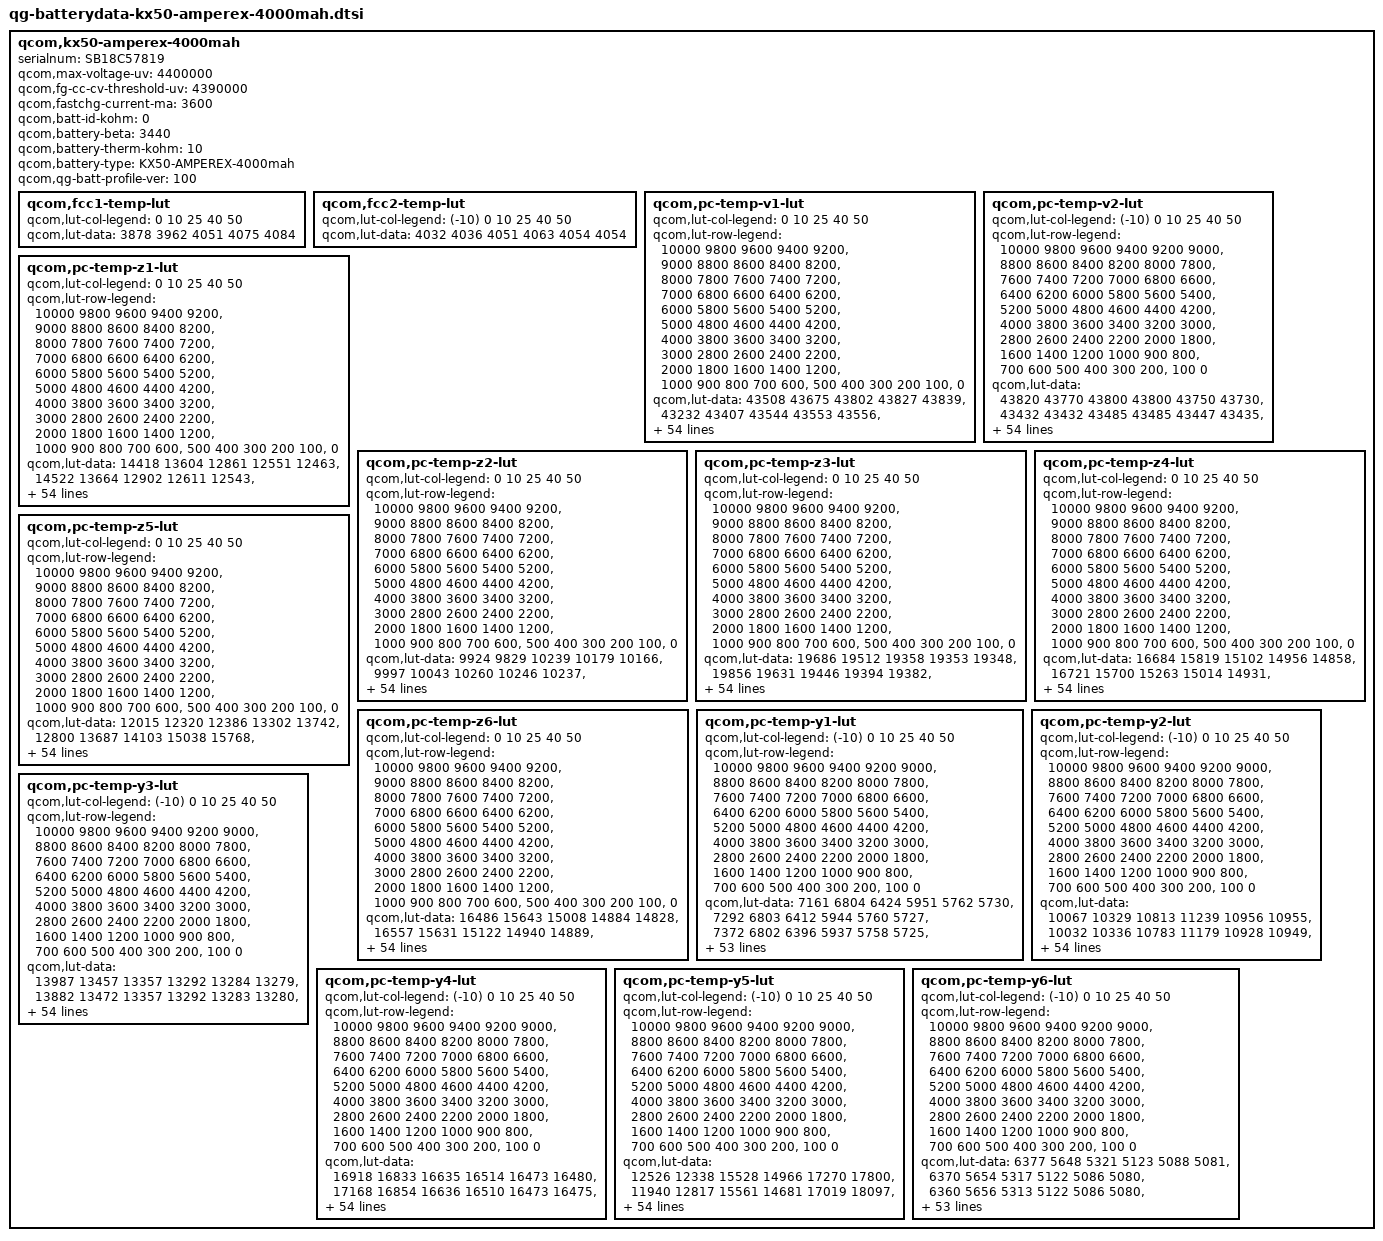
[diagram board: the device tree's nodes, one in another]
qcom,kx50-amperex-4000mah {
    /* 4151556_Lenovo_Sofia_ATL_4000mAH_PMI632_averaged_MasterSlave_Aug13th2019 */
    serialnum = "SB18C57819";
    qcom,max-voltage-uv = <4400000>;
    qcom,fg-cc-cv-threshold-uv = <4390000>;
    qcom,fastchg-current-ma = <3600>;
    qcom,batt-id-kohm = <0>;
    qcom,battery-beta = <3440>;
    qcom,battery-therm-kohm = <10>;
    qcom,battery-type = "KX50-AMPEREX-4000mah";
    qcom,qg-batt-profile-ver = <100>;

	qcom,fcc1-temp-lut {
		qcom,lut-col-legend = <0 10 25 40 50>;
		qcom,lut-data = <3878 3962 4051 4075 4084>;
	};

	qcom,fcc2-temp-lut {
		qcom,lut-col-legend = <(-10) 0 10 25 40 50>;
		qcom,lut-data = <4032 4036 4051 4063 4054 4054>;
	};

	qcom,pc-temp-v1-lut {
		qcom,lut-col-legend = <0 10 25 40 50>;
		qcom,lut-row-legend = <10000 9800 9600 9400 9200>,
			<9000 8800 8600 8400 8200>,
			<8000 7800 7600 7400 7200>,
			<7000 6800 6600 6400 6200>,
			<6000 5800 5600 5400 5200>,
			<5000 4800 4600 4400 4200>,
			<4000 3800 3600 3400 3200>,
			<3000 2800 2600 2400 2200>,
			<2000 1800 1600 1400 1200>,
			<1000 900 800 700 600>,
			<500 400 300 200 100>,
			<0>;
		qcom,lut-data = <43508 43675 43802 43827 43839>,
			<43232 43407 43544 43553 43556>,
			<42979 43149 43289 43306 43307>,
			<42740 42904 43037 43065 43072>,
			<42505 42667 42793 42824 42838>,
			<42275 42432 42554 42586 42606>,
			<42050 42201 42318 42351 42374>,
			<41830 41974 42083 42121 42141>,
			<41615 41749 41853 41894 41909>,
			<41412 41528 41627 41668 41683>,
			<41229 41320 41405 41442 41461>,
			<41045 41131 41194 41226 41244>,
			<40824 40939 40995 41021 41027>,
			<40569 40718 40796 40820 40817>,
			<40334 40483 40581 40612 40615>,
			<40135 40276 40366 40403 40421>,
			<39956 40094 40176 40212 40236>,
			<39802 39929 40004 40040 40060>,
			<39669 39784 39844 39876 39891>,
			<39544 39652 39705 39725 39735>,
			<39417 39513 39565 39578 39585>,
			<39294 39367 39376 39385 39398>,
			<39172 39209 39128 39106 39135>,
			<39051 39008 38913 38874 38904>,
			<38930 38774 38739 38745 38769>,
			<38805 38611 38598 38647 38664>,
			<38677 38511 38509 38554 38567>,
			<38565 38437 38445 38467 38477>,
			<38465 38380 38385 38387 38392>,
			<38380 38336 38322 38313 38308>,
			<38323 38296 38264 38245 38230>,
			<38280 38256 38213 38179 38160>,
			<38244 38218 38167 38119 38098>,
			<38212 38183 38123 38062 38039>,
			<38185 38152 38080 38012 37982>,
			<38157 38119 38038 37964 37927>,
			<38130 38087 37997 37917 37872>,
			<38097 38051 37957 37872 37818>,
			<38047 37997 37901 37811 37751>,
			<37976 37916 37819 37722 37658>,
			<37889 37818 37719 37618 37552>,
			<37769 37701 37611 37513 37443>,
			<37632 37567 37485 37396 37321>,
			<37478 37411 37328 37243 37164>,
			<37337 37269 37183 37101 37028>,
			<37233 37167 37084 37007 36943>,
			<37202 37137 37058 36976 36917>,
			<37185 37122 37038 36959 36896>,
			<37156 37098 37022 36939 36875>,
			<37110 37057 36979 36884 36810>,
			<36912 36846 36750 36635 36538>,
			<36470 36415 36322 36199 36098>,
			<35896 35842 35752 35626 35524>,
			<35111 35059 34975 34843 34737>,
			<33866 33831 33760 33626 33513>,
			<30000 30000 30000 30000 30000>;
	};

	qcom,pc-temp-v2-lut {
		qcom,lut-col-legend = <(-10) 0 10 25 40 50>;
		qcom,lut-row-legend = <10000 9800 9600 9400 9200 9000>,
			<8800 8600 8400 8200 8000 7800>,
			<7600 7400 7200 7000 6800 6600>,
			<6400 6200 6000 5800 5600 5400>,
			<5200 5000 4800 4600 4400 4200>,
			<4000 3800 3600 3400 3200 3000>,
			<2800 2600 2400 2200 2000 1800>,
			<1600 1400 1200 1000 900 800>,
			<700 600 500 400 300 200>,
			<100 0>;
		qcom,lut-data = <43820 43770 43800 43800 43750 43730>,
			<43432 43432 43485 43485 43447 43435>,
			<43083 43122 43192 43193 43164 43159>,
			<42775 42845 42923 42928 42903 42902>,
			<42500 42598 42678 42687 42664 42665>,
			<42260 42357 42439 42452 42429 42432>,
			<42068 42117 42202 42216 42194 42197>,
			<41888 41879 41969 41982 41961 41964>,
			<41647 41641 41742 41754 41732 41735>,
			<41334 41398 41520 41529 41506 41509>,
			<41115 41181 41304 41308 41284 41287>,
			<41030 41011 41100 41090 41065 41069>,
			<40956 40847 40898 40876 40851 40855>,
			<40732 40642 40687 40670 40647 40649>,
			<40234 40398 40467 40468 40449 40448>,
			<39832 40140 40256 40268 40257 40256>,
			<39617 39850 40058 40065 40066 40072>,
			<39441 39572 39862 39875 39885 39896>,
			<39253 39381 39654 39720 39723 39731>,
			<39065 39234 39440 39582 39575 39576>,
			<38890 39084 39236 39410 39403 39399>,
			<38725 38918 39041 39168 39181 39181>,
			<38574 38759 38864 38934 38963 38966>,
			<38445 38622 38712 38759 38784 38788>,
			<38330 38499 38579 38611 38626 38630>,
			<38238 38376 38459 38486 38496 38498>,
			<38167 38240 38351 38380 38389 38390>,
			<38106 38122 38252 38286 38295 38294>,
			<38049 38044 38161 38198 38206 38203>,
			<37997 37985 38077 38119 38126 38120>,
			<37947 37938 38003 38047 38055 38046>,
			<37899 37900 37932 37980 37990 37980>,
			<37850 37864 37873 37919 37929 37917>,
			<37799 37828 37826 37861 37869 37856>,
			<37748 37793 37786 37806 37810 37795>,
			<37693 37749 37746 37751 37737 37712>,
			<37631 37694 37707 37697 37644 37598>,
			<37565 37633 37664 37638 37553 37488>,
			<37493 37570 37611 37569 37474 37402>,
			<37416 37501 37548 37492 37397 37323>,
			<37337 37421 37470 37410 37318 37242>,
			<37256 37321 37365 37319 37236 37159>,
			<37179 37209 37246 37207 37127 37048>,
			<37108 37085 37114 37074 36994 36914>,
			<37033 36970 36981 36944 36874 36803>,
			<36942 36867 36894 36888 36831 36770>,
			<36893 36825 36870 36874 36817 36755>,
			<36835 36777 36841 36855 36802 36738>,
			<36763 36721 36796 36825 36775 36702>,
			<36641 36634 36710 36739 36683 36569>,
			<36404 36422 36466 36467 36374 36184>,
			<35996 36005 35958 35971 35873 35658>,
			<35383 35397 35312 35331 35229 34968>,
			<34459 34522 34420 34450 34340 34011>,
			<32903 33093 33141 33226 33016 32750>,
			<28628 27862 28050 28115 27959 27941>;
	};

	qcom,pc-temp-z1-lut {
		qcom,lut-col-legend = <0 10 25 40 50>;
		qcom,lut-row-legend = <10000 9800 9600 9400 9200>,
			<9000 8800 8600 8400 8200>,
			<8000 7800 7600 7400 7200>,
			<7000 6800 6600 6400 6200>,
			<6000 5800 5600 5400 5200>,
			<5000 4800 4600 4400 4200>,
			<4000 3800 3600 3400 3200>,
			<3000 2800 2600 2400 2200>,
			<2000 1800 1600 1400 1200>,
			<1000 900 800 700 600>,
			<500 400 300 200 100>,
			<0>;
		qcom,lut-data = <14418 13604 12861 12551 12463>,
			<14522 13664 12902 12611 12543>,
			<14499 13692 12900 12616 12553>,
			<14453 13682 12897 12619 12560>,
			<14425 13661 12892 12618 12563>,
			<14409 13642 12883 12615 12564>,
			<14396 13624 12876 12614 12566>,
			<14387 13608 12868 12615 12569>,
			<14380 13595 12863 12617 12573>,
			<14376 13583 12860 12620 12578>,
			<14374 13571 12859 12626 12586>,
			<14371 13559 12859 12628 12590>,
			<14360 13546 12860 12629 12591>,
			<14330 13517 12862 12629 12591>,
			<14295 13478 12860 12629 12592>,
			<14252 13467 12856 12628 12592>,
			<14214 13475 12856 12628 12592>,
			<14208 13485 12857 12631 12594>,
			<14214 13488 12858 12634 12597>,
			<14222 13490 12862 12637 12598>,
			<14232 13495 12868 12639 12600>,
			<14243 13514 12871 12640 12601>,
			<14246 13534 12873 12641 12602>,
			<14245 13539 12876 12641 12603>,
			<14244 13541 12881 12643 12605>,
			<14245 13544 12887 12646 12607>,
			<14248 13549 12892 12650 12610>,
			<14252 13556 12898 12654 12612>,
			<14270 13562 12903 12659 12616>,
			<14289 13568 12908 12663 12620>,
			<14296 13570 12913 12666 12623>,
			<14298 13566 12920 12671 12627>,
			<14301 13561 12929 12676 12631>,
			<14305 13566 12937 12682 12635>,
			<14308 13587 12945 12688 12640>,
			<14315 13606 12952 12693 12645>,
			<14331 13616 12961 12698 12649>,
			<14350 13625 12970 12703 12652>,
			<14377 13637 12978 12707 12655>,
			<14408 13652 12985 12711 12658>,
			<14415 13661 12991 12715 12661>,
			<14402 13664 12997 12719 12665>,
			<14397 13668 13004 12723 12669>,
			<14429 13714 13018 12728 12671>,
			<14443 13720 13034 12734 12675>,
			<14436 13698 13035 12740 12676>,
			<14501 13707 13037 12738 12677>,
			<14482 13693 13031 12739 12679>,
			<14405 13696 13036 12742 12681>,
			<14422 13746 13044 12746 12685>,
			<14475 13729 13053 12752 12689>,
			<14523 13756 13065 12760 12698>,
			<14472 13813 13085 12774 12710>,
			<14547 13825 13105 12794 12729>,
			<14547 13825 13105 12794 12729>,
			<14547 13825 13105 12794 12729>;
	};

	qcom,pc-temp-z2-lut {
		qcom,lut-col-legend = <0 10 25 40 50>;
		qcom,lut-row-legend = <10000 9800 9600 9400 9200>,
			<9000 8800 8600 8400 8200>,
			<8000 7800 7600 7400 7200>,
			<7000 6800 6600 6400 6200>,
			<6000 5800 5600 5400 5200>,
			<5000 4800 4600 4400 4200>,
			<4000 3800 3600 3400 3200>,
			<3000 2800 2600 2400 2200>,
			<2000 1800 1600 1400 1200>,
			<1000 900 800 700 600>,
			<500 400 300 200 100>,
			<0>;
		qcom,lut-data = <9924 9829 10239 10179 10166>,
			<9997 10043 10260 10246 10237>,
			<10043 10150 10327 10349 10360>,
			<10078 10141 10360 10422 10426>,
			<10108 10118 10343 10426 10430>,
			<10138 10099 10303 10404 10398>,
			<10155 10083 10280 10376 10363>,
			<10155 10072 10269 10335 10339>,
			<10151 10065 10260 10297 10316>,
			<10146 10060 10250 10285 10292>,
			<10138 10059 10243 10279 10264>,
			<10125 10066 10244 10264 10253>,
			<10100 10075 10257 10173 10271>,
			<10050 10078 10266 10088 10293>,
			<10020 10081 10264 10087 10263>,
			<10012 10088 10261 10099 10166>,
			<10008 10113 10264 10112 10127>,
			<10009 10147 10282 10127 10130>,
			<10023 10177 10304 10145 10136>,
			<10034 10208 10322 10169 10154>,
			<10037 10223 10344 10204 10198>,
			<10038 10228 10394 10281 10273>,
			<10038 10232 10493 10495 10453>,
			<10034 10243 10539 10634 10581>,
			<10030 10262 10486 10487 10475>,
			<10035 10276 10416 10246 10275>,
			<10053 10285 10391 10209 10237>,
			<10069 10292 10377 10254 10277>,
			<10080 10289 10374 10280 10303>,
			<10090 10280 10411 10277 10301>,
			<10098 10276 10451 10273 10296>,
			<10105 10275 10451 10305 10280>,
			<10112 10275 10443 10425 10230>,
			<10120 10276 10440 10481 10194>,
			<10128 10281 10446 10440 10177>,
			<10139 10288 10455 10394 10168>,
			<10156 10298 10464 10395 10183>,
			<10172 10308 10475 10416 10240>,
			<10185 10318 10490 10445 10291>,
			<10197 10328 10516 10510 10337>,
			<10211 10336 10538 10562 10366>,
			<10225 10342 10543 10523 10360>,
			<10246 10351 10547 10439 10345>,
			<10286 10373 10553 10408 10345>,
			<10577 10520 10597 10406 10351>,
			<10673 10610 10635 10445 10348>,
			<10643 10612 10603 10427 10351>,
			<10442 10779 10604 10426 10366>,
			<10437 10792 10634 10445 10374>,
			<10456 10925 10636 10553 10433>,
			<10429 10820 10723 10542 10334>,
			<10320 10735 10614 10334 10111>,
			<10097 10633 10541 10238 10061>,
			<9948 10468 10639 10191 9981>,
			<9948 10468 10639 10191 9981>,
			<9948 10468 10639 10191 9981>;
	};

	qcom,pc-temp-z3-lut {
		qcom,lut-col-legend = <0 10 25 40 50>;
		qcom,lut-row-legend = <10000 9800 9600 9400 9200>,
			<9000 8800 8600 8400 8200>,
			<8000 7800 7600 7400 7200>,
			<7000 6800 6600 6400 6200>,
			<6000 5800 5600 5400 5200>,
			<5000 4800 4600 4400 4200>,
			<4000 3800 3600 3400 3200>,
			<3000 2800 2600 2400 2200>,
			<2000 1800 1600 1400 1200>,
			<1000 900 800 700 600>,
			<500 400 300 200 100>,
			<0>;
		qcom,lut-data = <19686 19512 19358 19353 19348>,
			<19856 19631 19446 19394 19382>,
			<19883 19695 19483 19414 19403>,
			<19896 19701 19505 19429 19412>,
			<19894 19703 19507 19439 19417>,
			<19850 19703 19509 19447 19421>,
			<19798 19693 19509 19450 19423>,
			<19763 19682 19508 19446 19427>,
			<19733 19674 19507 19439 19430>,
			<19723 19668 19503 19434 19429>,
			<19725 19657 19497 19430 19419>,
			<19729 19638 19487 19423 19412>,
			<19743 19623 19472 19408 19408>,
			<19780 19620 19463 19396 19405>,
			<19800 19619 19464 19395 19399>,
			<19791 19615 19465 19395 19388>,
			<19773 19586 19462 19394 19380>,
			<19753 19556 19449 19388 19376>,
			<19725 19545 19437 19381 19372>,
			<19709 19539 19430 19377 19367>,
			<19709 19538 19425 19373 19361>,
			<19709 19552 19431 19374 19361>,
			<19711 19573 19456 19390 19369>,
			<19726 19589 19469 19402 19375>,
			<19745 19604 19462 19388 19363>,
			<19762 19609 19451 19364 19339>,
			<19779 19608 19443 19357 19332>,
			<19786 19604 19435 19354 19331>,
			<19784 19600 19432 19353 19331>,
			<19782 19592 19434 19356 19344>,
			<19777 19585 19436 19362 19367>,
			<19764 19580 19438 19372 19376>,
			<19749 19575 19440 19391 19381>,
			<19736 19571 19442 19400 19382>,
			<19723 19568 19446 19398 19379>,
			<19707 19564 19449 19395 19372>,
			<19688 19560 19447 19389 19366>,
			<19674 19555 19441 19380 19360>,
			<19669 19552 19437 19376 19356>,
			<19666 19549 19434 19375 19353>,
			<19662 19545 19431 19374 19351>,
			<19656 19543 19425 19369 19352>,
			<19647 19539 19419 19363 19356>,
			<19625 19527 19417 19363 19363>,
			<19519 19484 19409 19360 19363>,
			<19489 19457 19397 19351 19347>,
			<19456 19447 19390 19351 19336>,
			<19330 19351 19386 19342 19335>,
			<19324 19340 19363 19339 19330>,
			<19324 19340 19356 19329 19324>,
			<19330 19400 19360 19331 19346>,
			<19335 19352 19358 19355 19368>,
			<19340 19350 19362 19361 19364>,
			<19345 19344 19335 19358 19369>,
			<19345 19344 19335 19358 19369>,
			<19345 19344 19335 19358 19369>;
	};

	qcom,pc-temp-z4-lut {
		qcom,lut-col-legend = <0 10 25 40 50>;
		qcom,lut-row-legend = <10000 9800 9600 9400 9200>,
			<9000 8800 8600 8400 8200>,
			<8000 7800 7600 7400 7200>,
			<7000 6800 6600 6400 6200>,
			<6000 5800 5600 5400 5200>,
			<5000 4800 4600 4400 4200>,
			<4000 3800 3600 3400 3200>,
			<3000 2800 2600 2400 2200>,
			<2000 1800 1600 1400 1200>,
			<1000 900 800 700 600>,
			<500 400 300 200 100>,
			<0>;
		qcom,lut-data = <16684 15819 15102 14956 14858>,
			<16721 15700 15263 15014 14931>,
			<16553 15573 15183 14989 14924>,
			<16210 15425 15086 14943 14897>,
			<15979 15271 15021 14906 14872>,
			<15829 15161 14965 14872 14846>,
			<15709 15081 14918 14843 14821>,
			<15612 15017 14879 14822 14799>,
			<15533 14966 14846 14803 14779>,
			<15454 14924 14820 14783 14762>,
			<15373 14893 14799 14762 14748>,
			<15294 14870 14782 14752 14736>,
			<15217 14850 14769 14749 14726>,
			<15142 14828 14757 14747 14719>,
			<15083 14807 14747 14740 14716>,
			<15041 14801 14739 14730 14714>,
			<15009 14802 14730 14720 14711>,
			<14982 14802 14723 14709 14702>,
			<14960 14795 14715 14699 14693>,
			<14939 14775 14705 14692 14686>,
			<14913 14758 14697 14686 14681>,
			<14885 14741 14707 14695 14687>,
			<14859 14731 14754 14771 14760>,
			<14832 14756 14801 14837 14829>,
			<14812 14826 14845 14857 14851>,
			<14806 14855 14877 14870 14863>,
			<14802 14853 14876 14869 14864>,
			<14801 14848 14860 14856 14850>,
			<14809 14838 14842 14839 14830>,
			<14819 14822 14823 14820 14800>,
			<14819 14806 14802 14797 14763>,
			<14813 14792 14783 14769 14736>,
			<14807 14779 14764 14734 14714>,
			<14801 14767 14747 14713 14701>,
			<14796 14755 14730 14703 14696>,
			<14794 14745 14718 14698 14693>,
			<14793 14737 14713 14698 14693>,
			<14792 14731 14711 14699 14694>,
			<14786 14730 14711 14701 14696>,
			<14776 14732 14720 14716 14712>,
			<14772 14732 14727 14729 14728>,
			<14772 14730 14726 14728 14724>,
			<14771 14728 14722 14726 14714>,
			<14770 14728 14719 14727 14713>,
			<14775 14719 14705 14719 14705>,
			<14777 14710 14686 14698 14690>,
			<14805 14715 14682 14689 14689>,
			<14941 14811 14670 14679 14672>,
			<14943 14817 14679 14657 14650>,
			<14934 14809 14681 14660 14648>,
			<14929 14749 14705 14700 14672>,
			<14950 14824 14723 14690 14666>,
			<14963 14836 14724 14689 14674>,
			<14978 14852 14759 14696 14673>,
			<14978 14852 14759 14696 14673>,
			<14978 14852 14759 14696 14673>;
	};

	qcom,pc-temp-z5-lut {
		qcom,lut-col-legend = <0 10 25 40 50>;
		qcom,lut-row-legend = <10000 9800 9600 9400 9200>,
			<9000 8800 8600 8400 8200>,
			<8000 7800 7600 7400 7200>,
			<7000 6800 6600 6400 6200>,
			<6000 5800 5600 5400 5200>,
			<5000 4800 4600 4400 4200>,
			<4000 3800 3600 3400 3200>,
			<3000 2800 2600 2400 2200>,
			<2000 1800 1600 1400 1200>,
			<1000 900 800 700 600>,
			<500 400 300 200 100>,
			<0>;
		qcom,lut-data = <12015 12320 12386 13302 13742>,
			<12800 13687 14103 15038 15768>,
			<13155 14627 15155 15995 17274>,
			<13383 15094 15982 16884 17997>,
			<13427 15414 16357 17709 18489>,
			<13408 15705 16613 18530 18805>,
			<13377 15953 16985 18846 19201>,
			<13316 16219 17544 18705 20219>,
			<13224 16648 18088 18539 21277>,
			<13194 17132 18577 18733 21413>,
			<13292 17303 18979 19378 21378>,
			<13487 17329 19038 19601 21381>,
			<13909 17360 18950 18736 22217>,
			<14771 18140 18892 17866 23189>,
			<15249 19808 19554 18184 22932>,
			<15294 20237 20604 19222 21899>,
			<15317 18661 20865 20043 21528>,
			<15307 17179 20902 20563 22292>,
			<15235 17292 20974 21146 23383>,
			<15183 17996 21695 21936 24153>,
			<15492 19251 23397 23064 24899>,
			<16353 23614 29563 25884 26295>,
			<17505 29861 46286 34803 29853>,
			<19434 37264 54357 40710 32357>,
			<22174 46054 45801 33833 27882>,
			<26809 49009 33685 22059 19178>,
			<33603 45320 27980 18281 16124>,
			<37505 40000 24131 16970 15134>,
			<39113 36143 22666 16519 14767>,
			<40024 32669 22342 16558 15604>,
			<39389 30491 22191 16665 17338>,
			<36181 29144 22399 17659 19097>,
			<32833 28348 23252 21327 21153>,
			<30321 28337 24593 24749 22974>,
			<27975 28533 28051 27714 24701>,
			<25764 28631 31315 29749 25904>,
			<23379 28618 32367 29677 25957>,
			<22039 28600 32998 28875 25730>,
			<22246 28610 33043 28000 25324>,
			<22782 28656 31809 27174 23893>,
			<23166 28678 29928 26052 22218>,
			<23436 28332 27178 23228 21157>,
			<23477 27576 24775 20019 20476>,
			<22475 25625 24771 19891 22067>,
			<19113 23370 25244 19835 22600>,
			<17782 21752 25362 19212 19238>,
			<16300 19956 23160 19476 17221>,
			<12100 13177 22888 18430 17963>,
			<12010 12856 18062 19798 19761>,
			<12053 12973 17594 18465 19204>,
			<12211 15710 16914 15335 18515>,
			<12149 13062 15409 16441 20011>,
			<12007 12785 15147 16310 17693>,
			<11871 12430 13169 15192 17076>,
			<11871 12430 13169 15192 17076>,
			<11871 12430 13169 15192 17076>;
	};

	qcom,pc-temp-z6-lut {
		qcom,lut-col-legend = <0 10 25 40 50>;
		qcom,lut-row-legend = <10000 9800 9600 9400 9200>,
			<9000 8800 8600 8400 8200>,
			<8000 7800 7600 7400 7200>,
			<7000 6800 6600 6400 6200>,
			<6000 5800 5600 5400 5200>,
			<5000 4800 4600 4400 4200>,
			<4000 3800 3600 3400 3200>,
			<3000 2800 2600 2400 2200>,
			<2000 1800 1600 1400 1200>,
			<1000 900 800 700 600>,
			<500 400 300 200 100>,
			<0>;
		qcom,lut-data = <16486 15643 15008 14884 14828>,
			<16557 15631 15122 14940 14889>,
			<16479 15606 15105 14936 14892>,
			<16310 15550 15080 14929 14891>,
			<16176 15464 15056 14921 14888>,
			<16067 15399 15029 14911 14879>,
			<15973 15350 15006 14899 14869>,
			<15900 15309 14988 14888 14863>,
			<15839 15277 14972 14877 14857>,
			<15788 15250 14959 14867 14849>,
			<15744 15226 14946 14858 14840>,
			<15705 15203 14934 14849 14831>,
			<15667 15183 14920 14840 14826>,
			<15629 15165 14910 14832 14820>,
			<15596 15150 14905 14827 14814>,
			<15566 15135 14901 14823 14808>,
			<15539 15122 14895 14817 14801>,
			<15514 15110 14885 14810 14795>,
			<15491 15099 14876 14802 14789>,
			<15473 15088 14868 14796 14783>,
			<15460 15086 14863 14791 14778>,
			<15450 15089 14870 14797 14780>,
			<15448 15095 14905 14841 14819>,
			<15449 15114 14932 14872 14850>,
			<15451 15154 14946 14870 14849>,
			<15456 15170 14955 14867 14845>,
			<15466 15169 14953 14862 14841>,
			<15473 15167 14943 14856 14835>,
			<15479 15162 14934 14850 14828>,
			<15482 15153 14928 14844 14824>,
			<15480 15144 14922 14838 14820>,
			<15473 15137 14916 14833 14815>,
			<15464 15131 14910 14828 14809>,
			<15458 15126 14905 14824 14804>,
			<15452 15122 14901 14821 14799>,
			<15447 15119 14898 14817 14796>,
			<15442 15116 14895 14813 14792>,
			<15439 15115 14893 14810 14789>,
			<15441 15116 14892 14809 14788>,
			<15444 15119 14896 14814 14794>,
			<15448 15123 14898 14820 14800>,
			<15453 15125 14897 14818 14799>,
			<15455 15126 14894 14814 14797>,
			<15454 15125 14893 14815 14800>,
			<15421 15110 14886 14811 14798>,
			<15408 15096 14873 14797 14783>,
			<15404 15093 14867 14794 14778>,
			<15397 15086 14861 14785 14770>,
			<15395 15084 14853 14774 14757>,
			<15398 15085 14852 14771 14753>,
			<15408 15095 14866 14789 14777>,
			<15430 15110 14876 14801 14789>,
			<15453 15126 14883 14807 14794>,
			<15489 15147 14891 14813 14799>,
			<15489 15147 14891 14813 14799>,
			<15489 15147 14891 14813 14799>;
	};

	qcom,pc-temp-y1-lut {
		qcom,lut-col-legend = <(-10) 0 10 25 40 50>;
		qcom,lut-row-legend = <10000 9800 9600 9400 9200 9000>,
			<8800 8600 8400 8200 8000 7800>,
			<7600 7400 7200 7000 6800 6600>,
			<6400 6200 6000 5800 5600 5400>,
			<5200 5000 4800 4600 4400 4200>,
			<4000 3800 3600 3400 3200 3000>,
			<2800 2600 2400 2200 2000 1800>,
			<1600 1400 1200 1000 900 800>,
			<700 600 500 400 300 200>,
			<100 0>;
		qcom,lut-data = <7161 6804 6424 5951 5762 5730>,
			<7292 6803 6412 5944 5760 5727>,
			<7372 6802 6396 5937 5758 5725>,
			<7414 6801 6381 5931 5756 5722>,
			<7430 6799 6370 5925 5754 5720>,
			<7433 6797 6366 5920 5752 5719>,
			<7395 6795 6368 5916 5750 5718>,
			<7342 6793 6371 5913 5749 5717>,
			<7339 6786 6370 5909 5748 5715>,
			<7362 6771 6362 5904 5747 5714>,
			<7375 6764 6354 5902 5745 5713>,
			<7360 6770 6349 5901 5744 5713>,
			<7341 6780 6343 5900 5743 5713>,
			<7345 6784 6336 5900 5743 5713>,
			<7370 6787 6327 5899 5744 5713>,
			<7389 6788 6324 5898 5745 5713>,
			<7401 6786 6342 5900 5745 5714>,
			<7408 6783 6361 5902 5746 5715>,
			<7399 6787 6359 5903 5747 5716>,
			<7366 6799 6349 5903 5747 5716>,
			<7351 6805 6345 5904 5748 5716>,
			<7386 6805 6352 5906 5749 5717>,
			<7427 6805 6359 5909 5751 5718>,
			<7433 6806 6362 5913 5752 5719>,
			<7434 6808 6364 5918 5754 5721>,
			<7434 6808 6364 5922 5756 5722>,
			<7408 6797 6362 5926 5758 5724>,
			<7371 6786 6360 5929 5761 5725>,
			<7345 6787 6363 5933 5764 5727>,
			<7321 6794 6371 5939 5768 5730>,
			<7312 6804 6379 5944 5772 5733>,
			<7310 6827 6390 5952 5775 5736>,
			<7309 6844 6397 5958 5779 5738>,
			<7311 6844 6388 5963 5783 5741>,
			<7319 6842 6374 5967 5787 5743>,
			<7330 6838 6374 5972 5789 5745>,
			<7362 6824 6395 5978 5790 5747>,
			<7387 6813 6409 5982 5791 5749>,
			<7373 6818 6402 5984 5793 5751>,
			<7337 6829 6390 5986 5794 5753>,
			<7326 6832 6395 5990 5796 5753>,
			<7334 6831 6426 5996 5798 5753>,
			<7329 6818 6429 5998 5800 5754>,
			<7276 6766 6421 6002 5802 5758>,
			<7279 6770 6454 6013 5807 5762>,
			<7329 6813 6436 6024 5811 5764>,
			<7407 6817 6465 6028 5812 5765>,
			<7417 6813 6467 6027 5814 5765>,
			<7336 6793 6464 6030 5812 5765>,
			<7362 6851 6436 6030 5813 5766>,
			<7334 6840 6473 6037 5816 5770>,
			<7381 6827 6461 6052 5824 5777>,
			<7444 6852 6472 6077 5836 5787>,
			<7556 6874 6482 6116 5851 5800>,
			<7556 6874 6482 6116 5851 5800>,
			<7556 6874 6482 6116 5851 5800>;
	};

	qcom,pc-temp-y2-lut {
		qcom,lut-col-legend = <(-10) 0 10 25 40 50>;
		qcom,lut-row-legend = <10000 9800 9600 9400 9200 9000>,
			<8800 8600 8400 8200 8000 7800>,
			<7600 7400 7200 7000 6800 6600>,
			<6400 6200 6000 5800 5600 5400>,
			<5200 5000 4800 4600 4400 4200>,
			<4000 3800 3600 3400 3200 3000>,
			<2800 2600 2400 2200 2000 1800>,
			<1600 1400 1200 1000 900 800>,
			<700 600 500 400 300 200>,
			<100 0>;
		qcom,lut-data = <10067 10329 10813 11239 10956 10955>,
			<10032 10336 10783 11179 10928 10949>,
			<10017 10345 10754 11103 10901 10935>,
			<10017 10355 10727 11028 10875 10916>,
			<10028 10367 10704 10966 10851 10893>,
			<10046 10379 10686 10931 10828 10865>,
			<10087 10398 10670 10915 10804 10824>,
			<10154 10414 10658 10906 10785 10787>,
			<10256 10413 10659 10906 10778 10778>,
			<10425 10398 10668 10911 10774 10775>,
			<10507 10391 10672 10913 10772 10774>,
			<10463 10530 10666 10907 10771 10783>,
			<10404 10708 10659 10900 10771 10794>,
			<10416 10725 10684 10904 10787 10779>,
			<10501 10707 10774 10924 10845 10730>,
			<10587 10699 10835 10954 10898 10713>,
			<10672 10704 10859 11021 10931 10796>,
			<10737 10717 10877 11096 10969 10903>,
			<10571 10739 10892 11151 11062 10959>,
			<9981 10780 10904 11197 11208 11001>,
			<9695 10818 10921 11206 11254 11012>,
			<9686 10853 10946 11167 11208 10995>,
			<9681 10880 10976 11133 11151 10979>,
			<9677 10889 11007 11142 11116 10974>,
			<9673 10894 11040 11167 11089 10972>,
			<9670 10902 11066 11190 11083 10974>,
			<9668 10922 11088 11211 11086 11004>,
			<9667 10938 11105 11231 11092 11047>,
			<9665 10926 11117 11251 11119 11094>,
			<9664 10889 11126 11271 11169 11148>,
			<9663 10861 11128 11294 11204 11190>,
			<9662 10847 11120 11323 11226 11228>,
			<9661 10832 11109 11338 11249 11249>,
			<9660 10810 11100 11333 11284 11253>,
			<9659 10777 11090 11323 11319 11255>,
			<9659 10679 11074 11317 11312 11236>,
			<9658 10177 11047 11312 11233 11132>,
			<9658 9744 11015 11304 11169 11064>,
			<9657 9700 10985 11278 11148 11074>,
			<9657 9681 10952 11244 11136 11088>,
			<9657 9672 10909 11225 11142 11086>,
			<9656 9668 10852 11212 11172 11065>,
			<9656 9664 10793 11193 11160 11021>,
			<9656 9661 10728 11166 11088 10963>,
			<9655 9658 10642 11142 10996 10941>,
			<9655 9657 10574 11106 10998 10801>,
			<9655 9656 10520 11076 10933 10763>,
			<9655 9656 10484 11060 10994 10723>,
			<9654 9655 10439 11043 11005 10833>,
			<9654 9654 10398 11051 11005 10811>,
			<9653 9654 10273 11011 10949 10711>,
			<9653 9653 9783 10932 10854 10671>,
			<9651 9652 9681 10851 10802 10586>,
			<9649 9651 9661 10746 10697 10497>,
			<9649 9651 9661 10746 10697 10497>,
			<9649 9651 9661 10746 10697 10497>;
	};

	qcom,pc-temp-y3-lut {
		qcom,lut-col-legend = <(-10) 0 10 25 40 50>;
		qcom,lut-row-legend = <10000 9800 9600 9400 9200 9000>,
			<8800 8600 8400 8200 8000 7800>,
			<7600 7400 7200 7000 6800 6600>,
			<6400 6200 6000 5800 5600 5400>,
			<5200 5000 4800 4600 4400 4200>,
			<4000 3800 3600 3400 3200 3000>,
			<2800 2600 2400 2200 2000 1800>,
			<1600 1400 1200 1000 900 800>,
			<700 600 500 400 300 200>,
			<100 0>;
		qcom,lut-data = <13987 13457 13357 13292 13284 13279>,
			<13882 13472 13357 13292 13283 13280>,
			<13818 13482 13357 13292 13283 13281>,
			<13786 13490 13358 13292 13284 13282>,
			<13774 13494 13359 13292 13284 13283>,
			<13773 13496 13360 13293 13285 13284>,
			<13804 13492 13361 13294 13286 13284>,
			<13848 13486 13363 13294 13288 13285>,
			<13819 13486 13365 13297 13289 13285>,
			<13660 13491 13368 13302 13289 13286>,
			<13572 13494 13370 13305 13290 13287>,
			<13574 13473 13370 13305 13290 13287>,
			<13577 13447 13371 13305 13290 13288>,
			<13577 13444 13370 13307 13292 13288>,
			<13574 13446 13367 13312 13297 13288>,
			<13569 13446 13365 13314 13299 13289>,
			<13529 13434 13365 13311 13297 13291>,
			<13481 13418 13365 13308 13295 13294>,
			<13467 13412 13362 13309 13296 13295>,
			<13461 13409 13356 13313 13298 13296>,
			<13459 13405 13350 13313 13299 13296>,
			<13462 13397 13343 13309 13294 13291>,
			<13466 13389 13338 13303 13289 13284>,
			<13458 13382 13334 13298 13287 13282>,
			<13430 13377 13330 13294 13284 13281>,
			<13418 13370 13328 13292 13283 13280>,
			<13432 13358 13326 13292 13283 13280>,
			<13455 13347 13325 13292 13282 13280>,
			<13477 13338 13324 13293 13281 13279>,
			<13504 13330 13324 13295 13281 13278>,
			<13532 13328 13324 13296 13280 13278>,
			<13561 13339 13324 13297 13281 13278>,
			<13592 13353 13324 13297 13282 13279>,
			<13627 13360 13324 13297 13283 13281>,
			<13665 13364 13325 13297 13284 13282>,
			<13706 13370 13325 13297 13284 13282>,
			<13750 13375 13326 13298 13283 13280>,
			<13798 13383 13329 13299 13282 13279>,
			<13848 13395 13332 13298 13282 13279>,
			<13900 13413 13335 13297 13282 13280>,
			<13950 13435 13336 13296 13283 13282>,
			<13996 13464 13336 13296 13287 13285>,
			<14053 13508 13338 13297 13286 13285>,
			<14124 13583 13341 13297 13284 13282>,
			<14199 13693 13342 13295 13282 13279>,
			<14196 13747 13345 13297 13289 13288>,
			<14269 13837 13353 13302 13290 13290>,
			<14346 13935 13362 13305 13297 13294>,
			<14449 14059 13373 13313 13302 13297>,
			<14574 14176 13390 13318 13302 13296>,
			<14735 14284 13401 13315 13295 13291>,
			<14991 14450 13414 13316 13295 13293>,
			<15568 14708 13519 13325 13303 13298>,
			<17527 15102 13737 13337 13307 13307>,
			<17527 15102 13737 13337 13307 13307>,
			<17527 15102 13737 13337 13307 13307>;
	};

	qcom,pc-temp-y4-lut {
		qcom,lut-col-legend = <(-10) 0 10 25 40 50>;
		qcom,lut-row-legend = <10000 9800 9600 9400 9200 9000>,
			<8800 8600 8400 8200 8000 7800>,
			<7600 7400 7200 7000 6800 6600>,
			<6400 6200 6000 5800 5600 5400>,
			<5200 5000 4800 4600 4400 4200>,
			<4000 3800 3600 3400 3200 3000>,
			<2800 2600 2400 2200 2000 1800>,
			<1600 1400 1200 1000 900 800>,
			<700 600 500 400 300 200>,
			<100 0>;
		qcom,lut-data = <16918 16833 16635 16514 16473 16480>,
			<17168 16854 16636 16510 16473 16475>,
			<17329 16877 16637 16508 16473 16470>,
			<17420 16899 16639 16508 16473 16467>,
			<17461 16917 16640 16509 16473 16465>,
			<17470 16929 16641 16511 16473 16465>,
			<17399 16938 16641 16515 16474 16466>,
			<17299 16943 16641 16519 16475 16468>,
			<17322 16939 16643 16522 16478 16471>,
			<17504 16917 16651 16524 16483 16474>,
			<17674 16907 16661 16526 16488 16477>,
			<17797 17037 16673 16534 16495 16481>,
			<17884 17205 16689 16546 16503 16486>,
			<17765 17212 16724 16557 16507 16492>,
			<17276 17150 16785 16570 16511 16500>,
			<17026 17069 16809 16586 16517 16507>,
			<17029 16932 16806 16609 16530 16512>,
			<17034 16808 16799 16634 16548 16518>,
			<17033 16792 16769 16664 16571 16532>,
			<17028 16790 16695 16696 16600 16554>,
			<17017 16785 16639 16698 16607 16561>,
			<16947 16761 16601 16619 16578 16547>,
			<16869 16730 16575 16539 16539 16525>,
			<16857 16710 16564 16512 16508 16502>,
			<16854 16695 16557 16495 16480 16477>,
			<16851 16675 16556 16492 16473 16471>,
			<16848 16638 16556 16495 16475 16472>,
			<16845 16609 16556 16499 16479 16475>,
			<16841 16617 16555 16503 16487 16482>,
			<16836 16640 16553 16508 16498 16493>,
			<16835 16648 16549 16514 16510 16503>,
			<16836 16639 16541 16524 16523 16515>,
			<16838 16631 16535 16531 16533 16525>,
			<16839 16634 16539 16536 16538 16532>,
			<16841 16645 16550 16539 16541 16538>,
			<16843 16663 16561 16538 16537 16534>,
			<16845 16706 16574 16531 16509 16504>,
			<16846 16746 16586 16523 16490 16484>,
			<16846 16760 16597 16515 16488 16483>,
			<16845 16770 16606 16509 16487 16482>,
			<16845 16773 16612 16511 16489 16484>,
			<16857 16775 16616 16519 16496 16493>,
			<16870 16774 16616 16520 16496 16491>,
			<16885 16767 16612 16517 16489 16478>,
			<16903 16767 16606 16498 16470 16461>,
			<16877 16762 16600 16507 16473 16473>,
			<16890 16783 16624 16522 16495 16503>,
			<16917 16823 16657 16546 16521 16545>,
			<16948 16877 16708 16583 16561 16579>,
			<16967 16946 16768 16607 16573 16566>,
			<16957 16964 16791 16575 16507 16488>,
			<16928 16930 16793 16552 16491 16486>,
			<16953 16913 16851 16579 16499 16496>,
			<17432 16937 16952 16644 16540 16566>,
			<17432 16937 16952 16644 16540 16566>,
			<17432 16937 16952 16644 16540 16566>;
	};

	qcom,pc-temp-y5-lut {
		qcom,lut-col-legend = <(-10) 0 10 25 40 50>;
		qcom,lut-row-legend = <10000 9800 9600 9400 9200 9000>,
			<8800 8600 8400 8200 8000 7800>,
			<7600 7400 7200 7000 6800 6600>,
			<6400 6200 6000 5800 5600 5400>,
			<5200 5000 4800 4600 4400 4200>,
			<4000 3800 3600 3400 3200 3000>,
			<2800 2600 2400 2200 2000 1800>,
			<1600 1400 1200 1000 900 800>,
			<700 600 500 400 300 200>,
			<100 0>;
		qcom,lut-data = <12526 12338 15528 14966 17270 17800>,
			<11940 12817 15561 14681 17019 18097>,
			<11674 13412 15559 14410 16780 18276>,
			<11677 13995 15529 14159 16558 18366>,
			<11896 14433 15479 13930 16360 18398>,
			<12289 14597 15415 13730 16192 18399>,
			<14416 14533 15321 13521 16072 17914>,
			<17104 14412 15214 13368 15953 17104>,
			<16740 14312 15133 13498 15737 16574>,
			<13408 14221 15072 14030 15376 16163>,
			<11571 14080 14967 14273 14982 15790>,
			<13227 13625 14546 13913 14472 15461>,
			<15863 13145 14109 13504 14071 15136>,
			<17478 14037 14106 13469 14166 14690>,
			<18765 17516 14305 13469 14576 14149>,
			<19219 19199 14707 13470 14724 13967>,
			<17873 17770 16894 13487 14106 14264>,
			<15861 16075 19243 13526 13455 14588>,
			<14670 16216 19777 14315 13524 14631>,
			<13733 17251 20029 16465 13961 14642>,
			<13396 17804 20049 18255 14710 14729>,
			<13385 17876 19331 19859 17007 15703>,
			<13376 17940 18400 20792 18918 16886>,
			<13026 18358 17797 19650 18900 17589>,
			<12002 19288 17293 17213 18595 18142>,
			<11566 19545 17071 16389 18156 18212>,
			<11578 17421 16973 16237 17288 17494>,
			<11604 14847 16928 16178 16388 16531>,
			<11686 13706 17183 16590 15695 15540>,
			<11873 12919 17790 17468 15126 14568>,
			<12037 12786 18207 18132 15050 14380>,
			<12162 13878 18521 18675 15429 14644>,
			<12279 15193 18680 19128 15988 15077>,
			<12415 15921 18399 19458 16910 16140>,
			<12553 16480 17880 19753 17940 17483>,
			<12593 16456 17730 20183 18122 17699>,
			<12584 14741 17703 20786 17997 17406>,
			<12565 13254 17693 21055 17804 17135>,
			<12505 13241 17830 20238 17342 16985>,
			<12365 13294 18046 18886 16815 16883>,
			<12183 13283 17859 17840 17020 17261>,
			<11884 13053 16924 16983 18089 18702>,
			<11801 12808 16761 16947 18016 18839>,
			<11924 12606 16814 16981 17208 18156>,
			<12117 12605 16089 16761 16421 15595>,
			<12222 12600 15608 15839 16759 16777>,
			<12439 12761 15772 15847 15496 15520>,
			<12517 12712 15682 15593 16458 15225>,
			<12786 12819 15569 15998 16508 15185>,
			<12983 13118 15871 16301 15955 15328>,
			<12901 13042 15634 16836 15809 16294>,
			<12613 12810 13336 17816 17334 16844>,
			<12139 12638 12940 18753 19520 18693>,
			<10745 12208 12830 19605 20102 22405>,
			<10745 12208 12830 19605 20102 22405>,
			<10745 12208 12830 19605 20102 22405>;
	};

	qcom,pc-temp-y6-lut {
		qcom,lut-col-legend = <(-10) 0 10 25 40 50>;
		qcom,lut-row-legend = <10000 9800 9600 9400 9200 9000>,
			<8800 8600 8400 8200 8000 7800>,
			<7600 7400 7200 7000 6800 6600>,
			<6400 6200 6000 5800 5600 5400>,
			<5200 5000 4800 4600 4400 4200>,
			<4000 3800 3600 3400 3200 3000>,
			<2800 2600 2400 2200 2000 1800>,
			<1600 1400 1200 1000 900 800>,
			<700 600 500 400 300 200>,
			<100 0>;
		qcom,lut-data = <6377 5648 5321 5123 5088 5081>,
			<6370 5654 5317 5122 5086 5080>,
			<6360 5656 5313 5122 5086 5080>,
			<6350 5656 5309 5122 5086 5080>,
			<6342 5654 5306 5122 5086 5080>,
			<6337 5652 5302 5123 5087 5081>,
			<6336 5646 5299 5123 5088 5081>,
			<6335 5638 5297 5125 5089 5082>,
			<6323 5629 5297 5127 5091 5084>,
			<6280 5620 5298 5130 5093 5085>,
			<6257 5616 5299 5133 5095 5087>,
			<6288 5634 5301 5136 5097 5088>,
			<6330 5658 5303 5139 5099 5090>,
			<6305 5658 5310 5143 5102 5092>,
			<6188 5644 5323 5150 5106 5095>,
			<6116 5625 5328 5156 5110 5097>,
			<6103 5582 5328 5161 5113 5100>,
			<6094 5540 5326 5166 5116 5103>,
			<6083 5534 5317 5175 5123 5109>,
			<6071 5533 5290 5186 5132 5116>,
			<6061 5530 5270 5187 5135 5117>,
			<6051 5521 5254 5162 5123 5109>,
			<6045 5513 5243 5134 5107 5098>,
			<6046 5512 5239 5123 5096 5089>,
			<6051 5511 5236 5115 5087 5081>,
			<6058 5510 5235 5114 5084 5079>,
			<6078 5504 5236 5115 5085 5079>,
			<6103 5499 5237 5117 5086 5080>,
			<6128 5504 5239 5119 5088 5082>,
			<6154 5521 5241 5123 5091 5084>,
			<6182 5540 5242 5126 5094 5087>,
			<6212 5562 5244 5130 5099 5091>,
			<6244 5587 5245 5133 5103 5095>,
			<6277 5614 5250 5136 5105 5098>,
			<6312 5643 5257 5137 5107 5101>,
			<6348 5674 5265 5137 5106 5100>,
			<6385 5706 5274 5137 5097 5090>,
			<6424 5742 5285 5136 5092 5083>,
			<6465 5784 5297 5133 5092 5084>,
			<6507 5833 5310 5131 5092 5085>,
			<6549 5886 5323 5132 5093 5087>,
			<6590 5945 5337 5135 5097 5092>,
			<6638 6015 5355 5137 5097 5091>,
			<6696 6100 5378 5138 5094 5085>,
			<6762 6211 5399 5133 5088 5079>,
			<6772 6263 5415 5139 5095 5090>,
			<6836 6347 5452 5148 5102 5100>,
			<6906 6445 5492 5158 5115 5115>,
			<6997 6562 5545 5174 5130 5127>,
			<7103 6679 5607 5185 5133 5122>,
			<7232 6779 5657 5175 5109 5097>,
			<7447 6908 5717 5172 5106 5099>,
			<7946 7123 5888 5193 5115 5107>,
			<9691 7457 6178 5228 5132 5137>,
			<9691 7457 6178 5228 5132 5137>,
			<9691 7457 6178 5228 5132 5137>;
	};

};
